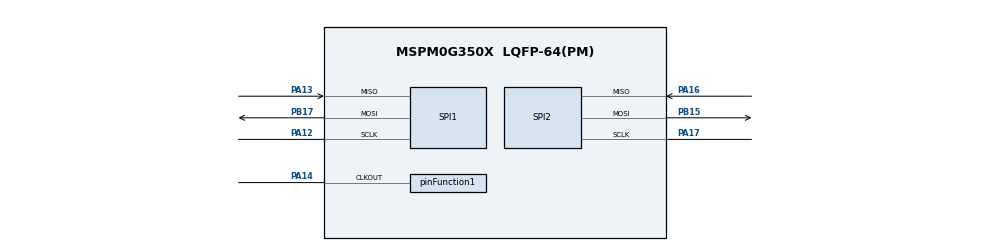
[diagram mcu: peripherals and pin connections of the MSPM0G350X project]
/**
 * @cliArgs --device "MSPM0G350X" --package "LQFP-64(PM)" --part "Default" --product "mspm0_sdk@2.00.01.01"
 * @versions {"tool":"1.19.0+3426"}
 */

/**
 * Import the modules used in this configuration.
 */
const DMA   = scripting.addModule("/ti/driverlib/DMA");
const GPIO  = scripting.addModule("/ti/driverlib/GPIO", {}, false);
const GPIO1 = GPIO.addInstance();
const GPIO2 = GPIO.addInstance();
const SPI   = scripting.addModule("/ti/driverlib/SPI", {}, false);
const SPI1  = SPI.addInstance();
const SPI2  = SPI.addInstance();

/**
 * Write custom configuration values to the imported modules.
 */
const divider1       = system.clockTree["EXCLKDIV"];
divider1.divideValue = 2;

const divider6       = system.clockTree["PLL_CLK2X_DIV"];
divider6.divideValue = 4;

const divider7       = system.clockTree["PLL_PDIV"];
divider7.divideValue = 2;

const divider9       = system.clockTree["UDIV"];
divider9.divideValue = 2;

const gate4  = system.clockTree["EXCLKGATE"];
gate4.enable = true;

const multiplier2         = system.clockTree["PLL_QDIV"];
multiplier2.multiplyValue = 6;

const mux3       = system.clockTree["EXCLKMUX"];
mux3.inputSelect = "EXCLKMUX_PLLCLK1_OUT";

const mux8       = system.clockTree["HSCLKMUX"];
mux8.inputSelect = "HSCLKMUX_SYSPLL0";

const pinFunction1                        = system.clockTree["CLKOUT"];
pinFunction1.enable                       = true;
pinFunction1.peripheral.clkOutPin.$assign = "PA14";

const Board = scripting.addModule("/ti/driverlib/Board", {}, false);

GPIO1.$name                          = "GPIO_L18";
GPIO1.associatedPins.create(2);
GPIO1.associatedPins[0].assignedPort = "PORTA";
GPIO1.associatedPins[0].assignedPin  = "25";
GPIO1.associatedPins[0].$name        = "START";
GPIO1.associatedPins[1].$name        = "RESET";
GPIO1.associatedPins[1].ioStructure  = "SD";
GPIO1.associatedPins[1].assignedPort = "PORTA";
GPIO1.associatedPins[1].assignedPin  = "8";

GPIO2.port                           = "PORTB";
GPIO2.$name                          = "GPIO_SPI";
GPIO2.associatedPins.create(4);
GPIO2.associatedPins[0].$name        = "CS";
GPIO2.associatedPins[0].initialValue = "SET";
GPIO2.associatedPins[0].assignedPin  = "6";
GPIO2.associatedPins[1].$name        = "SCLK";
GPIO2.associatedPins[1].assignedPin  = "9";
GPIO2.associatedPins[2].$name        = "MOSI";
GPIO2.associatedPins[2].assignedPin  = "8";
GPIO2.associatedPins[3].$name        = "MISO";
GPIO2.associatedPins[3].assignedPin  = "7";

SPI1.mode                                  = "PERIPHERAL";
SPI1.frameFormat                           = "MOTO3";
SPI1.rxFifoThreshold                       = "DL_SPI_RX_FIFO_LEVEL_ONE_FRAME";
SPI1.txFifoThreshold                       = "DL_SPI_TX_FIFO_LEVEL_3_4_EMPTY";
SPI1.enabledInterrupts                     = ["DMA_DONE_RX"];
SPI1.enabledDMAEvent1Triggers              = "DL_SPI_DMA_INTERRUPT_RX";
SPI1.$name                                 = "SPI_PERIPHERAL";
SPI1.peripheral.$assign                    = "SPI0";
SPI1.peripheral.sclkPin.$assign            = "PA12";
SPI1.peripheral.mosiPin.$assign            = "PB17";
SPI1.peripheral.misoPin.$assign            = "PA13";
SPI1.sclkPinConfig.onlyInternalResistor    = scripting.forceWrite(false);
SPI1.sclkPinConfig.passedPeripheralType    = scripting.forceWrite("Digital");
SPI1.sclkPinConfig.$name                   = "ti_driverlib_gpio_GPIOPinGeneric4";
SPI1.mosiPinConfig.hideOutputInversion     = scripting.forceWrite(false);
SPI1.mosiPinConfig.onlyInternalResistor    = scripting.forceWrite(false);
SPI1.mosiPinConfig.passedPeripheralType    = scripting.forceWrite("Digital");
SPI1.mosiPinConfig.$name                   = "ti_driverlib_gpio_GPIOPinGeneric5";
SPI1.misoPinConfig.onlyInternalResistor    = scripting.forceWrite(false);
SPI1.misoPinConfig.passedPeripheralType    = scripting.forceWrite("Digital");
SPI1.misoPinConfig.$name                   = "ti_driverlib_gpio_GPIOPinGeneric6";
SPI1.DMA_CHANNEL_EVENT1.$name              = "DMA_CH0";
SPI1.DMA_CHANNEL_EVENT1.addressMode        = "f2b";
SPI1.DMA_CHANNEL_EVENT1.srcLength          = "BYTE";
SPI1.DMA_CHANNEL_EVENT1.dstLength          = "BYTE";
SPI1.DMA_CHANNEL_EVENT1.peripheral.$assign = "DMA_CH0";

SPI2.mode                                  = "PERIPHERAL";
SPI2.frameFormat                           = "MOTO3";
SPI2.rxFifoThreshold                       = "DL_SPI_RX_FIFO_LEVEL_ONE_FRAME";
SPI2.txFifoThreshold                       = "DL_SPI_TX_FIFO_LEVEL_3_4_EMPTY";
SPI2.enabledInterrupts                     = ["DMA_DONE_RX"];
SPI2.enabledDMAEvent1Triggers              = "DL_SPI_DMA_INTERRUPT_RX";
SPI2.$name                                 = "SPI_PERIPHERAL2";
SPI2.peripheral.$assign                    = "SPI1";
SPI2.peripheral.sclkPin.$assign            = "PA17";
SPI2.peripheral.mosiPin.$assign            = "PB15";
SPI2.peripheral.misoPin.$assign            = "PA16";
SPI2.sclkPinConfig.onlyInternalResistor    = scripting.forceWrite(false);
SPI2.sclkPinConfig.passedPeripheralType    = scripting.forceWrite("Digital");
SPI2.sclkPinConfig.$name                   = "ti_driverlib_gpio_GPIOPinGeneric4_COPY";
SPI2.mosiPinConfig.hideOutputInversion     = scripting.forceWrite(false);
SPI2.mosiPinConfig.onlyInternalResistor    = scripting.forceWrite(false);
SPI2.mosiPinConfig.passedPeripheralType    = scripting.forceWrite("Digital");
SPI2.mosiPinConfig.$name                   = "ti_driverlib_gpio_GPIOPinGeneric5_COPY";
SPI2.misoPinConfig.onlyInternalResistor    = scripting.forceWrite(false);
SPI2.misoPinConfig.passedPeripheralType    = scripting.forceWrite("Digital");
SPI2.misoPinConfig.$name                   = "ti_driverlib_gpio_GPIOPinGeneric6_COPY";
SPI2.DMA_CHANNEL_EVENT1.$name              = "DMA_CH1";
SPI2.DMA_CHANNEL_EVENT1.addressMode        = "f2b";
SPI2.DMA_CHANNEL_EVENT1.srcLength          = "BYTE";
SPI2.DMA_CHANNEL_EVENT1.dstLength          = "BYTE";
SPI2.DMA_CHANNEL_EVENT1.peripheral.$assign = "DMA_CH1";

const SYSCTL                 = scripting.addModule("/ti/driverlib/SYSCTL", {}, false);
SYSCTL.forceDefaultClkConfig = true;
SYSCTL.clockTreeEn           = true;

/**
 * Pinmux solution for unlocked pins/peripherals. This ensures that minor changes to the automatic solver in a future
 * version of the tool will not impact the pinmux you originally saw.  These lines can be completely deleted in order to
 * re-solve from scratch.
 */
pinFunction1.peripheral.$suggestSolution     = "SYSCTL";
Board.peripheral.$suggestSolution            = "DEBUGSS";
Board.peripheral.swclkPin.$suggestSolution   = "PA20";
Board.peripheral.swdioPin.$suggestSolution   = "PA19";
GPIO1.associatedPins[0].pin.$suggestSolution = "PA25";
GPIO1.associatedPins[1].pin.$suggestSolution = "PA8";
GPIO2.associatedPins[0].pin.$suggestSolution = "PB6";
GPIO2.associatedPins[1].pin.$suggestSolution = "PB9";
GPIO2.associatedPins[2].pin.$suggestSolution = "PB8";
GPIO2.associatedPins[3].pin.$suggestSolution = "PB7";
